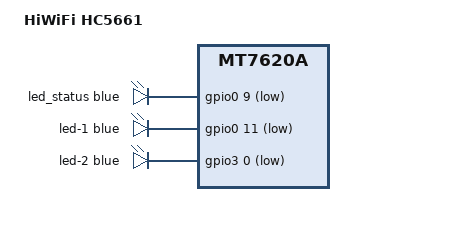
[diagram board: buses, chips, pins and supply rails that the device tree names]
#include "mt7620a_hiwifi_hc5x61.dtsi"

/ {
	compatible = "hiwifi,hc5661", "ralink,mt7620a-soc";
	model = "HiWiFi HC5661";

	aliases {
		label-mac-device = &ethernet;
		led-boot = &led_status;
		led-failsafe = &led_status;
		led-running = &led_status;
		led-upgrade = &led_status;
	};

	leds {
		compatible = "gpio-leds";

		led_status: led-0 {
			color = <LED_COLOR_ID_BLUE>;
			function = LED_FUNCTION_STATUS;
			gpios = <&gpio0 9 GPIO_ACTIVE_LOW>;
		};

		led-1 {
			color = <LED_COLOR_ID_BLUE>;
			function = LED_FUNCTION_WAN;
			gpios = <&gpio0 11 GPIO_ACTIVE_LOW>;
		};

		led-2 {
			color = <LED_COLOR_ID_BLUE>;
			function = LED_FUNCTION_WLAN;
			gpios = <&gpio3 0 GPIO_ACTIVE_LOW>;
			linux,default-trigger = "phy0tpt";
		};
	};
};

&usbphy {
	status = "disabled";
};
